# R7FA6M3AH register map
Vendor: Renesas; Series: RA6; File version: 1.2
CPU: CM4 r0p1, little endian, MPU, FPU, VTOR, 4 interrupt priority bits
Registers are 32-bit, read-write, reset 0x0 unless marked. A register's access mark holds for its fields unless they carry their own. Offsets are from the block's base; [hi:lo] are bit positions; {n}, {i} and the like mark numbered series.

## DRW — 2D Drawing Engine
Base 0x400E4000
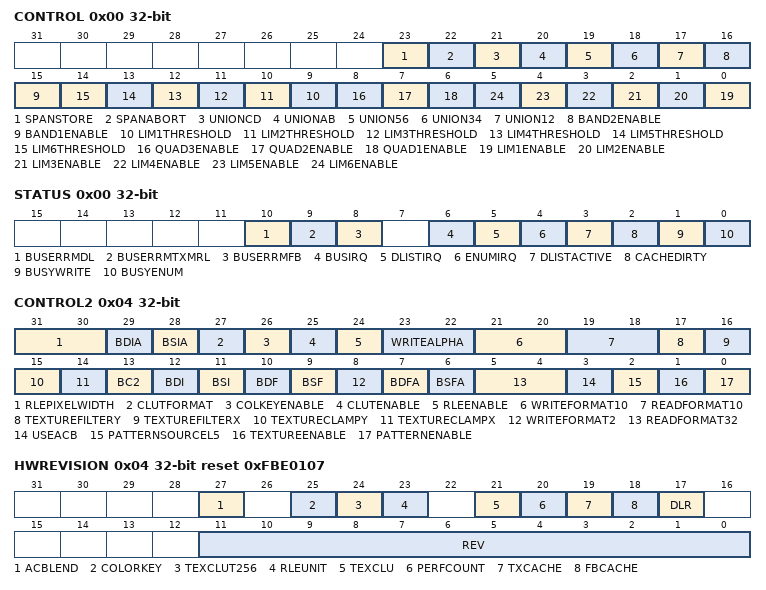
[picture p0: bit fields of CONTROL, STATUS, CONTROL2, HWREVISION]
0x00 CONTROL wo — Geometry Control Register
  [23] SPANSTORE — Nextline span start is always equal or left to current,line span start
  [22] SPANABORT — Shape is horizontally convex, only a single span per scanline
  [21] UNIONCD — Combine outputs C & D as union (output is final)
  [20] UNIONAB — Combine outputs A & B as union (output is called C)
  [19] UNION56 — Combine limter 5 & 6 as union (output is called D)
  [18] UNION34 — Combine limter 3 & 4 as union (output is called B)
  [17] UNION12 — Combine limter 1 & 2 as union (output is called A)
  [16] BAND2ENABLE — Enable band postprocess for limiter 1 (see L1BAND)
  [15] BAND1ENABLE — Enable band postprocess for limiter 1 (see L1BAND)
  [n+8] LIM{n}THRESHOLD (n=1..6) — Enable limiter {n} threshold mode
  [8] QUAD3ENABLE — Enable quadratic coupling of limiters 5 and 6
  [7] QUAD2ENABLE — Enable quadratic coupling of limiters 3 and 4
  [6] QUAD1ENABLE — Enable quadratic coupling of limiters 1 and 2
  [n-1] LIM{n}ENABLE (n=1..6) — Enable limiter {n}
0x00 STATUS ro (alternate view of CONTROL) — Status Control Register
  [10] BUSERRMDL — display list bus error interrupt triggered
  [9] BUSERRMTXMRL — texture bus error interrupt triggered
  [8] BUSERRMFB — framebuffer bus error interrupt triggered
  [6] BUSIRQ — bus error interrupt triggered
  [5] DLISTIRQ — display list finished interrupt triggered
  [4] ENUMIRQ — enumeration finished interrupt triggered
  [3] DLISTACTIVE — Display list reader status
  [2] CACHEDIRTY — Framebuffer cache status
  [1] BUSYWRITE — Framebuffer writeback status
  [0] BUSYENUM — Enumeration unit status
0x04 CONTROL2 wo — Surface Control Register
  [31:30] RLEPIXELWIDTH — Texel width for RLE unit
  [29] BDIA — Blend destination factor inverted in alpha channel (USEACB = 1)
  [28] BSIA — Blend source factor inverted in alpha channel (USEACB = 1)
  [27] CLUTFORMAT — Format of the CLUT
  [26] COLKEYENABLE — color keying enable
  [25] CLUTENABLE
  [24] RLEENABLE
  [23:22] WRITEALPHA — Writeback alpha source for framebufferSet the 'alpha source' for the framebuffer(USEACB = 0)Blend alpha in color 2 instead of framebuffer alpha((USEACB = 1))In not alpha channel blending mode (USEACB = 0):Set the 'alpha source' for the framebuffer.In alpha channel blending mode (USEACB = 1):Blend alpha in color 2 instead of framebuffer alpha00B: BC2A = 1: use alpha from framebuffer as destination (DST_A)else: BC2A = 0: use alpha in color 2 as destination (DST_A)
  [21:20] WRITEFORMAT10 — Pixel format of the framebuffer
  [19:18] READFORMAT10 — Pixel format of the texture buffer{READFORMAT32,READFORMAT10}0000: 8 bpp a(8)0001: 16 bpp RGB(565)0010: 32 bpp aRGB(8888)0011: 16 bpp aRGB(4444)0100: 16 bpp aRGB(1555)0101: 8 bpp aCLUT(44) 4 bit alpha and 4 bit indexed color1001: 8 bpp CLUT(8)/I(8), 8 bit indexed color/luminance1010: 4 bpp CLUT(4)/I(4), 4 bit indexed color/luminance1011: 2 bpp CLUT(2)/I(2), 2 bit indexed color/luminance 1100: 1 bpp CLUT(1)/I(1), 1 bit indexed color/luminance
  [17] TEXTUREFILTERY — Linear filtering on texture V axis
  [16] TEXTUREFILTERX — Linear filtering on texture U axis
  [15] TEXTURECLAMPY — Calculating V limiter outside use textureThe bit describes what happens if the V limiter (y direction in texture space) calculates a V value outside of the used texture
  [14] TEXTURECLAMPX — Calculating U limiter outside use textureThe bit describes what happens if the U limiter (x direction in texture space) calculates a U value outside of the used texture
  [13] BC2 — Blend color 2 instead of framebuffer pixel
  [12] BDI — Blend destination factor is inverteddst factor will be inverted (meaning 1-a or 1-1 depending on BDF)
  [11] BSI — Blend source factor is invertedsrc factor will be inverted (meaning 1-a or 1-1 depending on BSF)
  [10] BDF — Blend destination factordst factor is alpha (factor is 1 per default)
  [9] BSF — Blend source factorsrc factor is alpha (factor is 1 per default)
  [8] WRITEFORMAT2 — Bit 3 of framebuffer pixel formatSee WRITEFORMAT above description.
  [7] BDFA — Blend destinetion factor for alpha channel in alpha channel blending mode (USEACB = 1)
  [6] BSFA — Blend source factor for alpha channel in alpha channel blending mode (USEACB = 1)
  [5:4] READFORMAT32 — Bit 4 and 3 of the texture buffer format.See READFORMAT above for description
  [3] USEACB — Alpha blend mode
  [2] PATTERNSOURCEL5 — Limiter 5 is used as pattern index instead of the default U limiter.Limiter 5 can be combined with limiter 6 to form a quadratic limiter which can be used to make quadratic pattern functions to draw radial patterns.
  [1] TEXTUREENABLE — Pixel source is read from texture and used as an alpha to blend between COLOR1 and COLOR2
  [0] PATTERNENABLE — Pixel source is a pattern color (blend of COLOR1 and COLOR2 depending on PATTERN and pattern index)
0x04 HWREVISION ro reset 0xFBE0107 (alternate view of CONTROL2) — Hardware Version and Feature Set ID Register
  [27] ACBLEND — Alpha channel blending feature
  [25] COLORKEY — Colorkey feature
  [24] TEXCLUT256 — Texture CLUT feature
  [23] RLEUNIT — RLE unit feature
  [21] TEXCLU — Texture CLUT with 16 or 256 entries feature
  [20] PERFCOUNT — Two performance counter feature
  [19] TXCACHE — Texture cache feature
  [18] FBCACHE — Framebuffer cache feature
  [17] DLR — Display list reader feature
  [11:0] REV — Revision number
{0xC+4i} L{i}START (i=1..6) wo — Limiter {i} Start Value Register
  [31:0] LSTART — Start value of the n'th limiter(n=1-6)
{0x24+4i} L{i}XADD (i=1..6) wo — Limiter {i} X,Axis Increment Register
  [31:0] LXADD — X,axis increment
{0x3C+4i} L{i}YADD (i=1..6) wo — Limiter {i} Y,Axis Increment Register
  [31:0] LYADD — Y,axis increment
{0x54+4i} L{i}BAND (i=1..2) wo — Limiter {i} Band Width Parameter Register
  [31:0] LBAND — Limiter m band width parameter
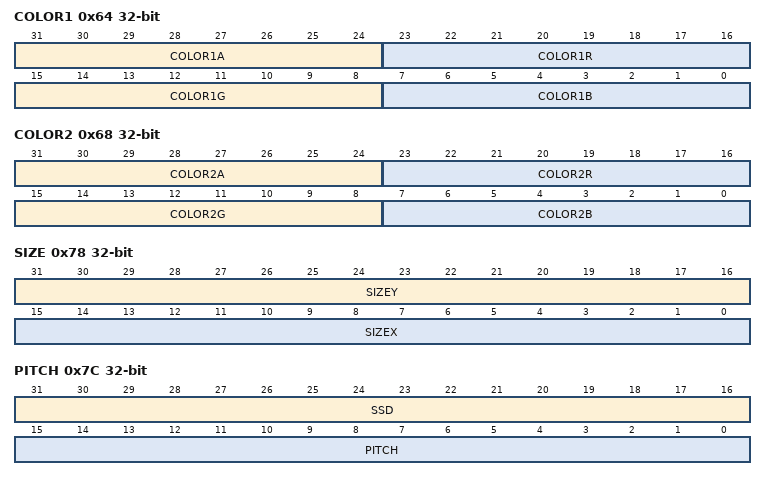
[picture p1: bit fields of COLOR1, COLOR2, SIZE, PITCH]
0x64 COLOR1 wo — Base Color Register
  [31:24] COLOR1A — Alpha channel of color 1(0x00: transparent. . . 0xFF: opaque)
  [23:16] COLOR1R — Red channel of color 1
  [15:8] COLOR1G — Green channel of color 1
  [7:0] COLOR1B — Blue channel of color 1
0x68 COLOR2 wo — Secondary Color Register
  [31:24] COLOR2A — Alpha channel of color 2(0x00: transparent. . . 0xFF: opaque)
  [23:16] COLOR2R — Red channel of color 2
  [15:8] COLOR2G — Green channel of color 2
  [7:0] COLOR2B — Blue channel of color 2
0x74 PATTERN wo
  [7:0] PATTERN — Bitmap of the pattern
0x78 SIZE wo — Bounding Box Dimension Register
  [31:16] SIZEY — Height of the bounding box in pixelsvalid range: 0 to 1024
  [15:0] SIZEX — Width of the bounding box in pixelsvalid range: 0 to 1024
0x7C PITCH wo — Framebuffer Pitch And Spanstore Delay Register
  [31:16] SSD — Spanstore delay
  [15:0] PITCH — pitch of the framebuffer. A negative width can be used to render bottom,up instead of top,down
0x80 ORIGIN wo — Framebuffer Base Address Register
  [31:0] ORIGIN — Address of the first pixel in framebuffer
0x90 LUSTART wo — U Limiter Start Value Register
  [31:0] LUSTART — U limiter start value
0x94 LUXADD wo — U Limiter X,Axis Increment Register
  [31:0] LUXADD — U limiter x,axis increment
0x98 LUYADD wo — U Limiter Y,Axis Increment Register
  [31:0] LUYADD — U limiter y,axis increment
0x9C LVSTARTI wo — V Limiter Start Value Integer Part Register
  [31:0] LVSTARTI — V limiter start value integer part
0xA0 LVSTARTF wo — V Limiter Start Value Fractional Part Register
  [15:0] LVSTARTF — V limiter start value fractional part
0xA4 LVXADDI wo — V Limiter X,Axis Increment Integer Part Register
  [31:0] LVXADDI — V limiter x,axis increment integer part
0xA8 LVYADDI wo — V Limiter Y,Axis Increment Integer Part Register
  [31:0] LVYADDI — V limiter y,axis increment integer part
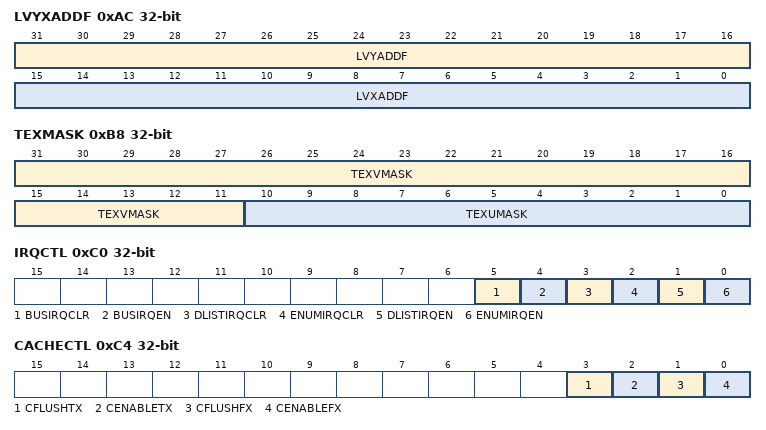
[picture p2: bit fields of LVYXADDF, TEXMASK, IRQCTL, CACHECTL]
0xAC LVYXADDF wo — V Limiter Increment Fractional Parts Register
  [31:16] LVYADDF — V y limiter increment fractional part
  [15:0] LVXADDF — V xlimiter increment fractional part
0xB4 TEXPITCH wo — Texels Per Texture Line Register
  [31:0] TEXPITCH — Texels per texture linevalid range: 0 to 2048
0xB8 TEXMASK wo — Texture Size or Texture Address Mask Register
  [31:11] TEXVMASK — V maskSet TEXVMASK[20:0] = TEXPITCH * (texture_height - 1).In texture wrapping mode (CONTROL2.TEXTURECLAMPY = 0): texture_height must be a power of 2In texture clamping mode (CONTROL2.TEXTURECLAMPY = 1):all heights up to 1024 are allowed.
  [10:0] TEXUMASK — U maskSet TEXUMASK[10:0] = texture_width -1In texture wrapping mode (CONTROL2.TEXTURECLAMPX = 0): texture_width must be a power of 2.In texture clamping mode (CONTROL2.TEXTURECLAMPX = 1):all widths up to 2048 are allowed.
0xBC TEXORIGIN wo — Texture Base Address Register
  [31:0] TEXORIGIN — Texture base address
0xC0 IRQCTL wo — Interrupt Control Register
  [5] BUSIRQCLR — Clear bus error interrupt BUSIRQ
  [4] BUSIRQEN — BUSIRQ interrupt mask enable
  [3] DLISTIRQCLR — Clear display list interrupt DLISTIRQ
  [2] ENUMIRQCLR — Clear enumeration interrupt ENUMIRQ
  [1] DLISTIRQEN — DLISTIRQ interrupt mask enable
  [0] ENUMIRQEN — ENUMIRQ interrupt mask enable
0xC4 CACHECTL wo — Cache Control Register
  [3] CFLUSHTX — Flush texture cache
  [2] CENABLETX — Texture cache enable
  [1] CFLUSHFX — Flush framebuffer cache
  [0] CENABLEFX — Framebuffer cache enable
0xC8 DLISTSTART wo — Display List Start Address Register
  [31:0] DLISTSTART — Display list start address
{0xC8+4i} PERFCOUNT{i} (i=1..2) — Performance Counter {i}
  [31:0] PERFCOUNT — Counter value.The counter is reset by writing PERFCOUNT = 0000 0000H.
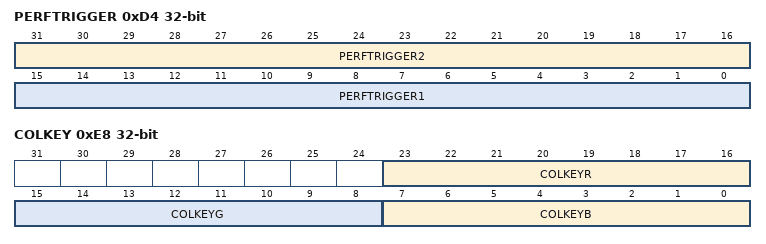
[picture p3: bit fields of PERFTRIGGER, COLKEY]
0xD4 PERFTRIGGER wo — Performance Counters Control Register
  [31:16] PERFTRIGGER2 — Selects the internal event that will increment PERFCOUNT2 register
  [15:0] PERFTRIGGER1 — Selects the internal event that will increment PERFCOUNT1 register.
0xDC TEXCLADDR wo — CLUT Start Address Register
  [7:0] CLADDR — Texture CLUT start address for indexed texture format
0xE0 TEXCLDATA wo — CLUT Data Register
  [31:0] CLDATA — Texture CLUT data for Indexed texture format
0xE4 TEXCLOFFSET wo — CLUT Offset Register
  [7:0] CLOFFSET — Texture CLUT offset for Indexed texture format. CLOFFSET[7:0] is or'ed with the original index
0xE8 COLKEY wo — Color Key Register
  [23:16] COLKEYR — Red channel of color key
  [15:8] COLKEYG — Green channel of color key
  [7:0] COLKEYB — Blue channel of color key
